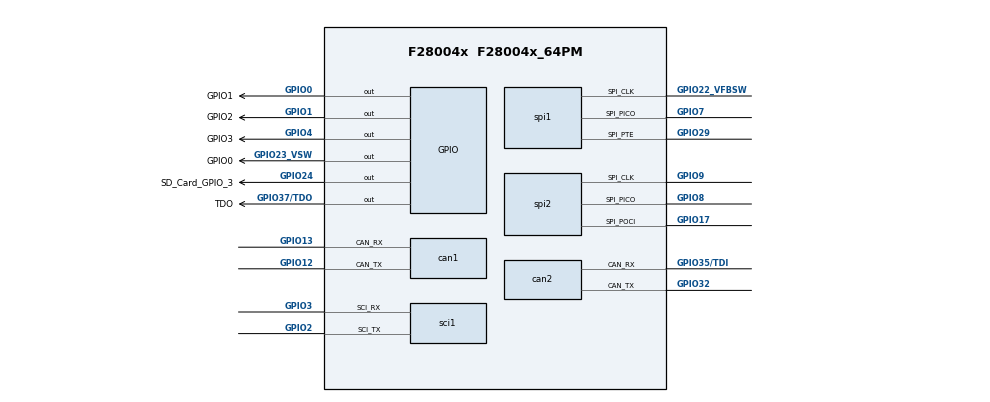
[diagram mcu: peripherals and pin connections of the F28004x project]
/**
 * @cliArgs --device "F28004x" --part "F28004x_64PM" --package "F28004x_64PM" --context "system" --product "C2000WARE@6.00.01.00"
 * @versions {"tool":"1.26.0+4407"}
 */

/**
 * Import the modules used in this configuration.
 */
const can    = scripting.addModule("/driverlib/can.js", {}, false);
const can1   = can.addInstance();
const can2   = can.addInstance();
const dcc    = scripting.addModule("/driverlib/dcc.js", {}, false);
const dcc1   = dcc.addInstance();
const flash  = scripting.addModule("/driverlib/flash.js", {}, false);
const flash1 = flash.addInstance();
const gpio   = scripting.addModule("/driverlib/gpio.js", {}, false);
const gpio1  = gpio.addInstance();
const gpio2  = gpio.addInstance();
const gpio3  = gpio.addInstance();
const gpio4  = gpio.addInstance();
const gpio5  = gpio.addInstance();
const gpio6  = gpio.addInstance();
const gpio7  = gpio.addInstance();
const gpio8  = gpio.addInstance();
const gpio9  = gpio.addInstance();
const sci    = scripting.addModule("/driverlib/sci.js", {}, false);
const sci1   = sci.addInstance();
const sci2   = sci.addInstance();
const spi    = scripting.addModule("/driverlib/spi.js", {}, false);
const spi1   = spi.addInstance();
const spi2   = spi.addInstance();

/**
 * Write custom configuration values to the imported modules.
 */
can1.$name                 = "GS_CAN";
can1.can.can_rxPin.$assign = "GPIO13";
can1.can.can_txPin.$assign = "GPIO12";

can2.$name                 = "LV_CAN";
can2.can.can_rxPin.$assign = "GPIO35/TDI";
can2.can.can_txPin.$assign = "GPIO32";

dcc1.$name = "myDCC0";

flash1.$name = "myFMC0";

gpio1.$name = "SPIB_STE2";

gpio2.$name = "SD_Card_GPIO_2";

gpio3.$name           = "SD_Card_GPIO_3";
gpio3.gpioPin.$assign = "GPIO24";

gpio4.$name           = "TDO";
gpio4.gpioPin.$assign = "GPIO37/TDO";

gpio5.$name           = "GPIO0";
gpio5.gpioPin.$assign = "GPIO23_VSW";

gpio6.$name           = "GPIO1";
gpio6.gpioPin.$assign = "GPIO0";

gpio7.$name           = "GPIO2";
gpio7.gpioPin.$assign = "GPIO1";

gpio8.$name           = "GPIO3";
gpio8.gpioPin.$assign = "GPIO4";

gpio9.$name = "TDI";

sci1.$name                 = "USB_SCI";
sci1.sci.sci_rxPin.$assign = "GPIO3";
sci1.sci.sci_txPin.$assign = "GPIO2";
sci1.rxQual.$name          = "myGPIOQUAL0";
sci1.txQual.$name          = "myGPIOQUAL1";

sci2.$name        = "LoRa_SCI";
sci2.rxQual.$name = "myGPIOQUAL10";
sci2.txQual.$name = "myGPIOQUAL11";

spi1.$name                   = "Flash";
spi1.spi.spi_picoPin.$assign = "GPIO7";
spi1.spi.spi_clkPin.$assign  = "GPIO22_VFBSW";
spi1.spi.spi_ptePin.$assign  = "GPIO29";
spi1.picoQual.$name          = "myGPIOQUAL2";
spi1.pociQual.$name          = "myGPIOQUAL3";
spi1.clkQual.$name           = "myGPIOQUAL4";
spi1.pteQual.$name           = "myGPIOQUAL5";

spi2.useInterrupts           = false;
spi2.mode                    = "SPI_MODE_CONTROLLER";
spi2.dataWidth               = "8";
spi2.transferProtocol        = "SPI_PROT_POL0PHA1";
spi2.$name                   = "SD_Card";
spi2.spi.spi_picoPin.$assign = "GPIO8";
spi2.spi.spi_pociPin.$assign = "GPIO17";
spi2.spi.spi_clkPin.$assign  = "GPIO9";
spi2.picoQual.$name          = "myGPIOQUAL6";
spi2.pociQual.$name          = "myGPIOQUAL7";
spi2.clkQual.$name           = "myGPIOQUAL8";
spi2.pteQual.$name           = "myGPIOQUAL9";

/**
 * Pinmux solution for unlocked pins/peripherals. This ensures that minor changes to the automatic solver in a future
 * version of the tool will not impact the pinmux you originally saw.  These lines can be completely deleted in order to
 * re-solve from scratch.
 */
can1.can.$suggestSolution             = "CANB";
can2.can.$suggestSolution             = "CANA";
gpio1.gpioPin.$suggestSolution        = "GPIO28";
gpio2.gpioPin.$suggestSolution        = "GPIO33";
gpio9.gpioPin.$suggestSolution        = "GPIO16";
sci1.sci.$suggestSolution             = "SCIA";
sci2.sci.$suggestSolution             = "SCIB";
sci2.sci.sci_rxPin.$suggestSolution   = "GPIO11";
sci2.sci.sci_txPin.$suggestSolution   = "GPIO10";
spi1.spi.$suggestSolution             = "SPIB";
spi1.spi.spi_pociPin.$suggestSolution = "GPIO6";
spi2.spi.$suggestSolution             = "SPIA";
spi2.spi.spi_ptePin.$suggestSolution  = "GPIO5";
